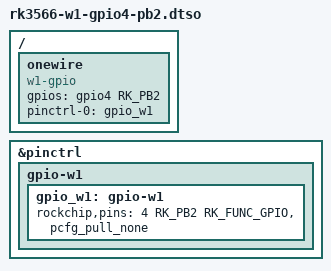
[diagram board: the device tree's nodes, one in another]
// SPDX-License-Identifier: (GPL-2.0+ OR MIT)

/dts-v1/;
/plugin/;

#include <dt-bindings/gpio/gpio.h>
#include <dt-bindings/pinctrl/rockchip.h>

/ {
    onewire: onewire {
        compatible = "w1-gpio";
        gpios = <&gpio4 RK_PB2 GPIO_ACTIVE_HIGH>;
        pinctrl-names = "default";
        pinctrl-0 = <&gpio_w1>;
        status = "okay";
    };
};

&pinctrl {
    gpio-w1 {
        gpio_w1:gpio-w1 {
            rockchip,pins = <4 RK_PB2 RK_FUNC_GPIO &pcfg_pull_none>;
        };
    };
};
